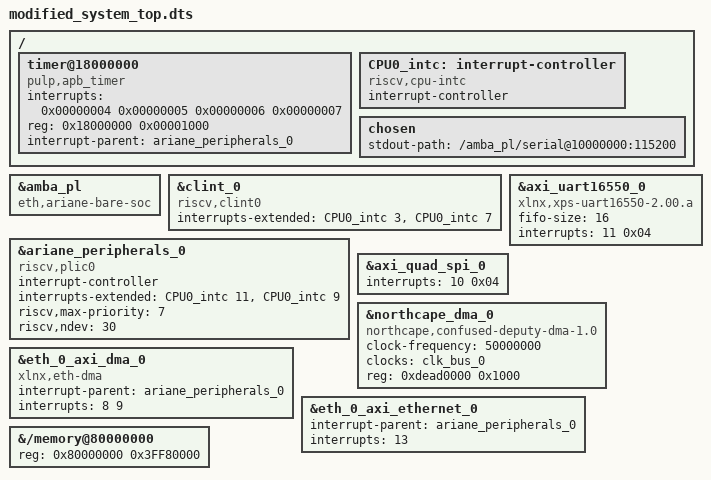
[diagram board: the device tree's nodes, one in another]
/dts-v1/;
/include/ "vitis_tmp/device_tree/system-top.dts"

/delete-node/ &{/chosen};
/delete-node/ &{/aliases};
/delete-node/ &{/cpus};

&amba_pl{
    compatible = "eth,ariane-bare-soc", "simple-bus";
};

&clint_0{
    compatible = "riscv,clint0", "sifive,clint0";
    interrupts-extended = <&CPU0_intc 3 &CPU0_intc 7>;
};

&ariane_peripherals_0{
    compatible = "riscv,plic0", "sifive,plic-1.0.0";
    #address-cells = <0>;
    #interrupt-cells = <1>;

    interrupt-controller;
    interrupts-extended = <&CPU0_intc 11 &CPU0_intc 9>;
    riscv,max-priority = <7>;
    riscv,ndev = <30>;
};

/{
    timer@18000000 {
      compatible = "pulp,apb_timer";
      interrupts = <0x00000004 0x00000005 0x00000006 0x00000007>;
      reg = <0x18000000 0x00001000>;
      interrupt-parent = <&ariane_peripherals_0>;
    };

    CPU0_intc: interrupt-controller {
        #interrupt-cells = <1>;
        interrupt-controller;
        compatible = "riscv,cpu-intc";
    };

    chosen {
        stdout-path = "/amba_pl/serial@10000000:115200";
        //tick-timer =  "/cpus/cpu@0";
    };
};

&axi_uart16550_0{
    compatible = "xlnx,xps-uart16550-2.00.a", "ns16550a", "ns16550";
    fifo-size = <16>;
    interrupts = <11 0x04>;
};

&axi_quad_spi_0{
    interrupts = <10 0x04>;
};

&northcape_dma_0 {
    #dma-cells = <1>;
    clock-frequency = <50000000>;
    clock-names = "s_axi_lite_aclk";
    clocks = <&clk_bus_0>;
    compatible = "northcape,confused-deputy-dma-1.0";
    reg = <0xdead0000 0x1000>;
};

&eth_0_axi_dma_0 {
    compatible="xlnx,eth-dma";
    status="okay";

    interrupt-parent = <&ariane_peripherals_0>;
    // RX - TX
    interrupts = <8 9>;
};

&eth_0_axi_ethernet_0 {
    interrupt-parent = <&ariane_peripherals_0>;
    interrupts = <13>;
};

// some of the memory is reserved for CMT
&{/memory@80000000} {
    reg = <0x80000000 0x3FF80000>;
};
